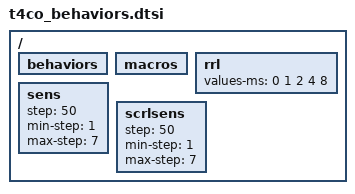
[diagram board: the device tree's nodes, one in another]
/ {
    /*
     * removing unused nodes to save memoryks
     */
    behaviors {
        /delete-node/ cdch;
        /delete-node/ cdc;
        /delete-node/ ltm;
        /delete-node/ ltmkp;
        /delete-node/ bst_copy;
        /delete-node/ bst_paste;
        /delete-node/ bst_cut;
        /delete-node/ bst_undo;
        /delete-node/ bst_tog;
    };

    macros {
        /delete-node/ winlin_copy;
        /delete-node/ macos_copy;
        /delete-node/ winlin_paste;
        /delete-node/ macos_paste;
        /delete-node/ winlin_cut;
        /delete-node/ macos_cut;
        /delete-node/ winlin_undo;
        /delete-node/ macos_undo;
        /delete-node/ scroll_down;
        /delete-node/ scroll_up;
        /delete-node/ scroll_left;
        /delete-node/ scroll_right;
    };
};


/ {
    /*
     * 0ms: No delay? report as fast as possible
     * 1ms: 1000Hz
     * 2ms: 500Hz
     * 4ms: 250Hz
     * 8ms: 125Hz
     */
    rrl {
        values-ms = <0 1 2 4 8>;
    };

    /*
     * 125 one step: 0.125
     * 1   min value: 0.1
     * 8   max value: 1 (8 steps)
     */

    /*
     * 50 step: 0.05
     * 1 min value: 0.05
     * 7 max value: 0.35
     */
    sens {
        step = <50>;
        min-step = <1>;
        max-step = <7>;
    };

    scrlsens {
        step = <50>;
        min-step = <1>;
        max-step = <7>;
    };
};
